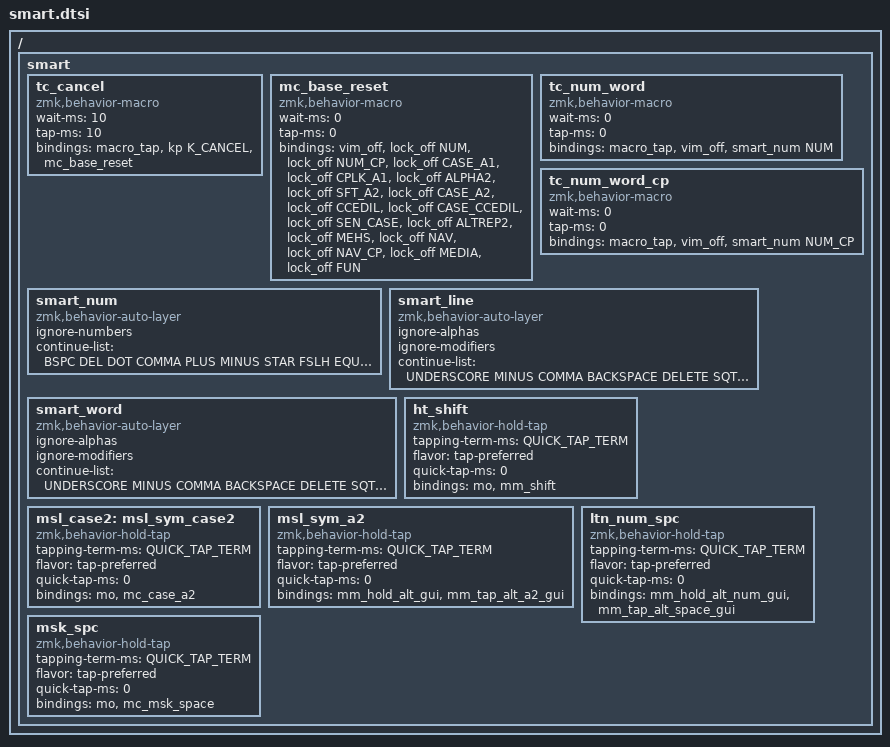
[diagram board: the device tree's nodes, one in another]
/*
*
* Copyright (c) 2022 Rafael Romão
* SPDX-License-Identifier: MIT
*
*/

/ {
    smart {
        
        // ********************** CANCEL ********************** //
        
        tc_cancel: tc_cancel {
            compatible = "zmk,behavior-macro";
            #binding-cells = <0>;
            wait-ms = <10>;
            tap-ms = <10>;
            // Clears the vim layers locally only. Cancel must not notify the
            // host (Meh+Esc), or it would toggle a sticky "off" override on
            // every press.
            bindings = <&macro_tap &kp K_CANCEL &mc_base_reset>;
        };

        /*
         * Everything a cancel should drop, named one by one.
         *
         * &to ALPHA1 would be shorter, but it means "this layer and the
         * default one, nothing else", and &to is itself a locking behavior:
         * it would clear ALT_OS -- a second base, held on by &lock_on -- in
         * spite of the lock. ALT_OS is deliberately absent from the list.
         *
         * &lock_off rather than &tog_off: the stock &tog on the toggles layer
         * and urob's auto-layer both activate *with* locking, and a non-locking
         * &tog_off against a locked layer is silently ignored, so MEHS and the
         * number layers would simply stay on. For an unlocked layer the two
         * behave identically. Layer toggles carry no keystrokes, hence no
         * pacing.
         */
        mc_base_reset: mc_base_reset {
            compatible = "zmk,behavior-macro";
            #binding-cells = <0>;
            wait-ms = <0>;
            tap-ms = <0>;
            bindings = <&vim_off &lock_off NUM &lock_off NUM_CP &lock_off CASE_A1 &lock_off CPLK_A1
                        &lock_off ALPHA2 &lock_off SFT_A2 &lock_off CASE_A2 &lock_off CCEDIL
                        &lock_off CASE_CCEDIL &lock_off SEN_CASE &lock_off ALTREP2 &lock_off MEHS
                        &lock_off NAV &lock_off NAV_CP &lock_off MEDIA &lock_off FUN>;
        };
        LAYERTAP_TP(lt_cancel,     &tc_cancel)

        // ********************** NUM WORD ********************** //

        smart_num: smart_num {
            compatible = "zmk,behavior-auto-layer";
            ignore-numbers;
            #binding-cells = <1>;
            continue-list = <BSPC DEL DOT COMMA PLUS MINUS STAR FSLH EQUAL AMPS PIPE HASH TILDE CARET LEFT RIGHT HOME END 
                             LBRC RBRC BACKSLASH DOLLAR AT LPAR RPAR DQT SQT LBKT RBKT QMARK GRAVE>;
        };

        tc_num_word: tc_num_word {
            compatible = "zmk,behavior-macro";
            #binding-cells = <0>;
            wait-ms = <0>;
            tap-ms = <0>;
            // &vim_off rather than &to ALPHA1: num word must type digits on
            // the base layout, but ALT_OS is a base too (see mc_base_reset).
            bindings = <&macro_tap &vim_off &smart_num NUM>;
        };

        tc_num_word_cp: tc_num_word_cp {
            compatible = "zmk,behavior-macro";
            #binding-cells = <0>;
            wait-ms = <0>;
            tap-ms = <0>;
            bindings = <&macro_tap &vim_off &smart_num NUM_CP>;
        };

        // ******************* CAPS LINE ******************* //

        smart_line: smart_line {
            compatible = "zmk,behavior-auto-layer";
            ignore-alphas;
            ignore-modifiers;
            #binding-cells = <1>;  
            continue-list = <UNDERSCORE MINUS COMMA BACKSPACE DELETE SQT TILDE CARET GRAVE LEFT RIGHT SPACE>;
        };
        // Lets go of the shift that armed it, as tc_smart_word does.
        MACRO(tc_smart_line, &smart_line CPLK_A1 &macro_release &kp LSHFT)

        // ******************* CAPS WORD ******************* //

        smart_word: smart_word {
            compatible = "zmk,behavior-auto-layer";
            ignore-alphas;
            ignore-modifiers;
            #binding-cells = <1>;  
            continue-list = <UNDERSCORE MINUS COMMA BACKSPACE DELETE SQT TILDE CARET GRAVE LEFT RIGHT>;
        };
        // Caps word is armed by a shift: the sticky one from the first tap on
        // the shift thumb, or a held home-row shift (see mm_shift). Only a key
        // press spends a sticky shift, so it used to still be down for the
        // first letter, which went out as Left Shift plus this layer's RS()
        // and then lost both shifts while it was still held. Linux typed that
        // letter lowercase, and the adaptive keys, which compare modifiers
        // strictly, missed their RS() triggers after it. The letters carry
        // their own shift, so let go of the one that armed the layer, as QMK's
        // caps word does. The sticky key is still spent by the first letter;
        // the shift it then releases is already up, and ZMK ignores that.
        MACRO(tc_smart_word, &smart_word CASE_A1 &macro_release &kp LSHFT)

        // ******************* SMART SHIFT ******************* //

        MACRO(tc_shift, &sk LSHFT)
        MOD_MORPH(mm_shift, MOD_LSFT|MOD_RSFT, &tc_smart_word, &tc_shift)
        MOD_MORPH(mm_repeat, MOD_LSFT|MOD_RSFT, &tc_smart_line, &alternate_repeat_key)

        ht_shift: ht_shift {
            compatible = "zmk,behavior-hold-tap";
            #binding-cells = <2>;
            tapping-term-ms = <QUICK_TAP_TERM>;
            flavor = "tap-preferred";
            quick-tap-ms = <0>;
            bindings = <&mo>, <&mm_shift>;
        };

        // ******************** SMART THUMBS ******************** //

        MACRO(mc_alpha2, &sl ALPHA2)
        MACRO(mc_sft_a2, &sl SFT_A2)
        MOD_MORPH(mm_alpha2_shifted2, MOD_LSFT|MOD_RSFT, &mc_sft_a2, &mc_alpha2)

        MACRO(mc_case_a2, &sl CASE_A2)
        LAYERTAP_TP(lt_sft_a2, &mc_sft_a2)

        msl_case2: msl_sym_case2 {
            compatible = "zmk,behavior-hold-tap";
            #binding-cells = <2>;
            tapping-term-ms = <QUICK_TAP_TERM>;
            flavor = "tap-preferred";
            quick-tap-ms = <0>;
            bindings = <&mo>, <&mc_case_a2>;
        };

        MACRO(mc_sk_rgui, &sk RGUI)
        MACRO(mc_hold_symbols, &macro_press &mo SYM &macro_pause_for_release &macro_release &mo SYM)
        MACRO(mc_hold_rgui, &macro_press &kp RGUI &macro_pause_for_release &macro_release &kp RGUI)
        MOD_MORPH_KM(mm_hold_sft_sym_gui, MOD_LSFT, &mc_hold_rgui, &mc_hold_symbols)
        MOD_MORPH_KM(mm_hold_ctl_sym_gui, MOD_LCTL, &mm_hold_sft_sym_gui, &mc_hold_symbols)
        MOD_MORPH_KM(mm_hold_alt_gui, MOD_LALT, &mm_hold_ctl_sym_gui, &mc_hold_symbols)
        MOD_MORPH_KM(mm_tap_sft_a2_gui, MOD_LSFT, &mc_sk_rgui, &mm_alpha2_shifted2)
        MOD_MORPH_KM(mm_tap_ctl_a2_gui, MOD_LCTL, &mm_tap_sft_a2_gui, &mm_alpha2_shifted2)
        MOD_MORPH_KM(mm_tap_alt_a2_gui, MOD_LALT, &mm_tap_ctl_a2_gui, &mm_alpha2_shifted2)

        msl_sym_a2: msl_sym_a2 {
            compatible = "zmk,behavior-hold-tap";
            #binding-cells = <2>;
            tapping-term-ms = <QUICK_TAP_TERM>;
            flavor = "tap-preferred";
            quick-tap-ms = <0>;
            bindings = <&mm_hold_alt_gui>, <&mm_tap_alt_a2_gui>;
        };

        MACRO(mc_space, &ak_space)
        MACRO(mc_sk_lgui, &sk LGUI)
        MACRO(mc_hold_numbers, &macro_press &mo NUM &macro_pause_for_release &macro_release &mo NUM)
        MACRO(mc_hold_lgui, &macro_press &kp LGUI &macro_pause_for_release &macro_release &kp LGUI)
        // Left-side modifiers, like the right thumb's chain above: the right
        // hand's home-row mods send LSFT/LALT/LCTL too (RALT would be AltGr on
        // Linux), so a chain keyed on MOD_R* could never fire.
        MOD_MORPH_KM(mm_hold_sft_num_gui, MOD_LSFT, &mc_hold_lgui, &mc_hold_numbers)
        MOD_MORPH_KM(mm_hold_ctl_num_gui, MOD_LCTL, &mm_hold_sft_num_gui, &mc_hold_numbers)
        MOD_MORPH_KM(mm_hold_alt_num_gui, MOD_LALT, &mm_hold_ctl_num_gui, &mc_hold_numbers)
        MOD_MORPH_KM(mm_tap_sft_space_gui, MOD_LSFT, &mc_sk_lgui, &mc_space)
        MOD_MORPH_KM(mm_tap_ctl_space_gui, MOD_LCTL, &mm_tap_sft_space_gui, &mc_space)
        MOD_MORPH_KM(mm_tap_alt_space_gui, MOD_LALT, &mm_tap_ctl_space_gui, &mc_space)

        ltn_num_spc: ltn_num_spc {
            compatible = "zmk,behavior-hold-tap";
            #binding-cells = <2>;
            tapping-term-ms = <QUICK_TAP_TERM>;
            flavor = "tap-preferred";
            quick-tap-ms = <0>;
            bindings = <&mm_hold_alt_num_gui>, <&mm_tap_alt_space_gui>;
        };

        // Ends num word: drop the number layers, leave the bases alone.
        // &lock_off, because auto-layer holds its layer locked (see mc_base_reset).
        MACRO(mc_msk_space, &kp SPACE &lock_off NUM &lock_off NUM_CP)

        msk_spc: msk_spc {
            compatible = "zmk,behavior-hold-tap";
            #binding-cells = <2>;
            tapping-term-ms = <QUICK_TAP_TERM>;
            flavor = "tap-preferred";
            quick-tap-ms = <0>;
            bindings = <&mo>, <&mc_msk_space>;
        };

    };
};
